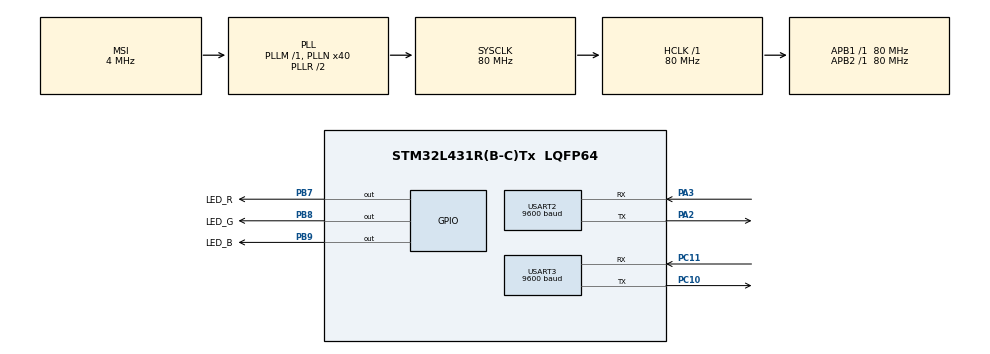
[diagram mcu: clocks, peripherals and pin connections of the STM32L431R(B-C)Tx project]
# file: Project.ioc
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Mcu.Family=STM32L4
Mcu.Name=STM32L431R(B-C)Tx
Mcu.Package=LQFP64
NVIC.PriorityGroup=NVIC_PRIORITYGROUP_4
NVIC.TIM1_UP_TIM16_IRQn=true\:0\:0\:false\:false\:true\:true\:true\:true
PA13\ (JTMS-SWDIO).Mode=Serial_Wire
PA13\ (JTMS-SWDIO).Signal=SYS_JTMS-SWDIO
PA14\ (JTCK-SWCLK).Mode=Serial_Wire
PA14\ (JTCK-SWCLK).Signal=SYS_JTCK-SWCLK
PA2.GPIO_PuPd=GPIO_NOPULL
PA2.Mode=Asynchronous
PA2.Signal=USART2_TX
PA3.Mode=Asynchronous
PA3.Signal=USART2_RX
PB7.GPIO_Label=LED_R
PB7.PinState=GPIO_PIN_SET
PB7.Signal=GPIO_Output
PB8.GPIO_Label=LED_G
PB8.PinState=GPIO_PIN_SET
PB8.Signal=GPIO_Output
PB9.GPIO_Label=LED_B
PB9.PinState=GPIO_PIN_SET
PB9.Signal=GPIO_Output
PC10.Mode=Asynchronous
PC10.Signal=USART3_TX
PC11.Mode=Asynchronous
PC11.Signal=USART3_RX
ProjectManager.HeapSize=0x200
ProjectManager.StackSize=0x400
ProjectManager.TargetToolchain=MDK-ARM V5
RCC.AHBFreq_Value=80000000
RCC.APB1Freq_Value=80000000
RCC.APB1TimFreq_Value=80000000
RCC.APB2Freq_Value=80000000
RCC.APB2TimFreq_Value=80000000
RCC.CortexFreq_Value=80000000
RCC.HCLKFreq_Value=80000000
RCC.HSE_VALUE=8000000
RCC.HSI48_VALUE=48000000
RCC.HSI_VALUE=16000000
RCC.LSE_VALUE=32768
RCC.MSI_VALUE=4000000
RCC.PLLN=40
RCC.SYSCLKFreq_VALUE=80000000
RCC.SYSCLKSource=RCC_SYSCLKSOURCE_PLLCLK
RCC.VCOOutputFreq_Value=160000000
TIM16.AutoReloadPreload=TIM_AUTORELOAD_PRELOAD_ENABLE
TIM16.Period=1000-1
TIM16.Prescaler=80-1
USART2.BaudRate=9600
USART2.VirtualMode-Asynchronous=VM_ASYNC
USART3.BaudRate=9600
USART3.VirtualMode-Asynchronous=VM_ASYNC
VP_TIM16_VS_ClockSourceINT.Mode=Enable_Timer
board=custom

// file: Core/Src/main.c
/* USER CODE BEGIN Header */
/**
  ******************************************************************************
  * @file           : main.c
  * @brief          : Main program body
  ******************************************************************************
  * @attention
  *
  * Copyright (c) 2024 STMicroelectronics.
  * All rights reserved.
  *
  * This software is licensed under terms that can be found in the LICENSE file
  * in the root directory of this software component.
  * If no LICENSE file comes with this software, it is provided AS-IS.
  *
  ******************************************************************************
  */
/* USER CODE END Header */
#include "main.h"
#include "tim.h"
#include "usart.h"
#include "gpio.h"

/* USER CODE BEGIN Includes */
#include "soft_tim.h"
#include "u2print.h"
/* USER CODE END Includes */

void SystemClock_Config(void);

int main(void)
{

  /* MCU Configuration--------------------------------------------------------*/

  /* Reset of all peripherals, Initializes the Flash interface and the Systick. */
  HAL_Init();

  /* Configure the system clock */
  SystemClock_Config();

  /* Initialize all configured peripherals */
  MX_GPIO_Init();
  MX_USART2_UART_Init();
  MX_USART3_UART_Init();
  MX_TIM16_Init();
  /* USER CODE BEGIN 2 */
  soft_timer_demo();
  /* USER CODE END 2 */

  /* Infinite loop */
  /* USER CODE BEGIN WHILE */
  while (1)
  {
    /* 串口发送 */
    uint8_t data[4] = {0x01, 0x02, 0x03, 0x04};
    // u2_send_n(data, 4);
u2_printf("%d\n",get_millis());
    HAL_Delay(100);
    /* USER CODE END WHILE */

  }
}

void SystemClock_Config(void)
{
  RCC_OscInitTypeDef RCC_OscInitStruct = {0};
  RCC_ClkInitTypeDef RCC_ClkInitStruct = {0};

  /** Configure the main internal regulator output voltage
  */
  if (HAL_PWREx_ControlVoltageScaling(PWR_REGULATOR_VOLTAGE_SCALE1) != HAL_OK)
  {
    Error_Handler();
  }

  /** Initializes the RCC Oscillators according to the specified parameters
  * in the RCC_OscInitTypeDef structure.
  */
  RCC_OscInitStruct.OscillatorType = RCC_OSCILLATORTYPE_MSI;
  RCC_OscInitStruct.MSIState = RCC_MSI_ON;
  RCC_OscInitStruct.MSICalibrationValue = 0;
  RCC_OscInitStruct.MSIClockRange = RCC_MSIRANGE_6;
  RCC_OscInitStruct.PLL.PLLState = RCC_PLL_ON;
  RCC_OscInitStruct.PLL.PLLSource = RCC_PLLSOURCE_MSI;
  RCC_OscInitStruct.PLL.PLLM = 1;
  RCC_OscInitStruct.PLL.PLLN = 40;
  RCC_OscInitStruct.PLL.PLLP = RCC_PLLP_DIV7;
  RCC_OscInitStruct.PLL.PLLQ = RCC_PLLQ_DIV2;
  RCC_OscInitStruct.PLL.PLLR = RCC_PLLR_DIV2;
  if (HAL_RCC_OscConfig(&RCC_OscInitStruct) != HAL_OK)
  {
    Error_Handler();
  }

  /** Initializes the CPU, AHB and APB buses clocks
  */
  RCC_ClkInitStruct.ClockType = RCC_CLOCKTYPE_HCLK|RCC_CLOCKTYPE_SYSCLK
                              |RCC_CLOCKTYPE_PCLK1|RCC_CLOCKTYPE_PCLK2;
  RCC_ClkInitStruct.SYSCLKSource = RCC_SYSCLKSOURCE_PLLCLK;
  RCC_ClkInitStruct.AHBCLKDivider = RCC_SYSCLK_DIV1;
  RCC_ClkInitStruct.APB1CLKDivider = RCC_HCLK_DIV1;
  RCC_ClkInitStruct.APB2CLKDivider = RCC_HCLK_DIV1;

  if (HAL_RCC_ClockConfig(&RCC_ClkInitStruct, FLASH_LATENCY_4) != HAL_OK)
  {
    Error_Handler();
  }
}

void Error_Handler(void)
{
  __disable_irq();
  while (1)
  {
  }
}
